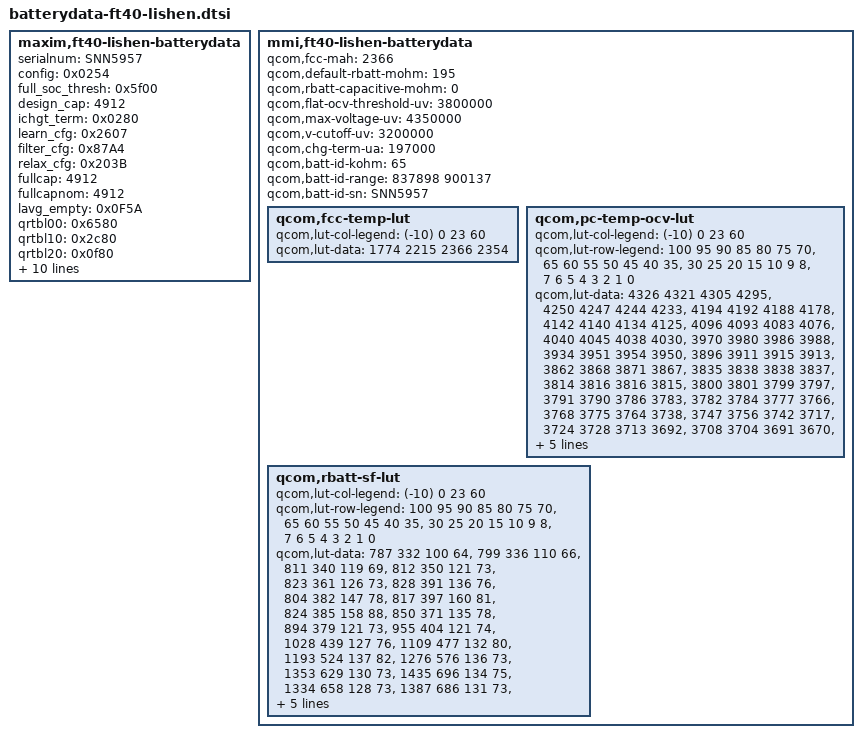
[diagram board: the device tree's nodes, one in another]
/* Copyright (c) 2013-2015, The Linux Foundation. All rights reserved.
 *
 * This program is free software; you can redistribute it and/or modify
 * it under the terms of the GNU General Public License version 2 and
 * only version 2 as published by the Free Software Foundation.
 *
 * This program is distributed in the hope that it will be useful,
 * but WITHOUT ANY WARRANTY; without even the implied warranty of
 * MERCHANTABILITY or FITNESS FOR A PARTICULAR PURPOSE.  See the
 * GNU General Public License for more details.
 */

maxim,ft40-lishen-batterydata {
	/* Required properties */
	serialnum	= "SNN5957";

	/* Table from Maxim for FT40 Lishen 2456 mAhr Battery */
	config		= /bits/ 16 <0x0254>;
	full_soc_thresh	= /bits/ 16 <0x5f00>;	/* app note constant */
	design_cap	= /bits/ 16 <4912>;	/* mAh times 2 */
	ichgt_term	= /bits/ 16 <0x0280>;	/* battery attribute */
	learn_cfg	= /bits/ 16 <0x2607>;	/* app note constant */
	filter_cfg	= /bits/ 16 <0x87A4>;	/* app note constant */
	relax_cfg	= /bits/ 16 <0x203B>;
	fullcap		= /bits/ 16 <4912>;	/* mAh times 2 */
	fullcapnom	= /bits/ 16 <4912>;	/* mAh times 2 */
	lavg_empty	= /bits/ 16 <0x0F5A>;	/* (2456mA/4/0.15625mA) */
	qrtbl00		= /bits/ 16 <0x6580>;	/* battery attribute */
	qrtbl10		= /bits/ 16 <0x2c80>;	/* battery attribute */
	qrtbl20		= /bits/ 16 <0x0f80>;	/* battery attribute */
	qrtbl30		= /bits/ 16 <0x0b00>;	/* battery attribute */
	rcomp0 		= /bits/ 16 <0x003f>;	/* battery attribute */
	tcompc0		= /bits/ 16 <0x1a3d>;	/* battery attribute */
	maxim,cell-char-tbl = /bits/ 16 <	/* battery attribute */
		0x9430 0xb340 0xb790 0xba00 0xbb50 0xbbd0
		0xbda0 0xbea0 0xc000 0xc320 0xc4d0 0xc760
		0xc9d0 0xcce0 0xd160 0xd720 0x0090 0x0600
		0x0d40 0x11a0 0x1910 0x1700 0x1b00 0x12e0
		0x09b0 0x0ce0 0x06e0 0x08e0 0x0790 0x07f0
		0x06e0 0x06e0 0x0200 0x0200 0x0200 0x0200
		0x0200 0x0200 0x0200 0x0200 0x0200 0x0200
		0x0200 0x0200 0x0200 0x0200 0x0200 0x0200
	>;
	/* Optional properties */
	tgain		= /bits/ 16 <0xE71C>;	/* thermistor attribute */
	toff		= /bits/ 16 <0x251A>;	/* thermistor attribute */
	cgain		= /bits/ 16 <0x4000>;	/* current sense attribute */
	misc_cfg	= /bits/ 16 <0x0170>;
	rev		= /bits/ 16 <0x0003>;
};

mmi,ft40-lishen-batterydata {
	qcom,fcc-mah = <2366>;
	qcom,default-rbatt-mohm = <195>;
	qcom,rbatt-capacitive-mohm = <0>;
	qcom,flat-ocv-threshold-uv = <3800000>;
	qcom,max-voltage-uv = <4350000>;
	qcom,v-cutoff-uv = <3200000>;
	qcom,chg-term-ua = <197000>;
	qcom,batt-id-kohm = <65>; /* 64.9 kOhm Round Up */
	qcom,batt-id-range = <837898 900137>;
	qcom,batt-id-sn = "SNN5957";

	qcom,fcc-temp-lut {
		qcom,lut-col-legend = <(-10) 0 23 60>;
		qcom,lut-data = <1774 2215 2366 2354>;
	};

	qcom,pc-temp-ocv-lut {
		qcom,lut-col-legend = <(-10) 0 23 60>;
		qcom,lut-row-legend = <100 95 90 85 80 75 70>,
				<65 60 55 50 45 40 35>,
				<30 25 20 15 10 9 8>,
				<7 6 5 4 3 2 1 0>;
		qcom,lut-data = <4326 4321 4305 4295>,
				<4250 4247 4244 4233>,
				<4194 4192 4188 4178>,
				<4142 4140 4134 4125>,
				<4096 4093 4083 4076>,
				<4040 4045 4038 4030>,
				<3970 3980 3986 3988>,
				<3934 3951 3954 3950>,
				<3896 3911 3915 3913>,
				<3862 3868 3871 3867>,
				<3835 3838 3838 3837>,
				<3814 3816 3816 3815>,
				<3800 3801 3799 3797>,
				<3791 3790 3786 3783>,
				<3782 3784 3777 3766>,
				<3768 3775 3764 3738>,
				<3747 3756 3742 3717>,
				<3724 3728 3713 3692>,
				<3708 3704 3691 3670>,
				<3705 3701 3691 3669>,
				<3702 3700 3690 3667>,
				<3697 3697 3688 3665>,
				<3687 3693 3684 3660>,
				<3665 3678 3667 3639>,
				<3626 3642 3630 3600>,
				<3569 3590 3579 3546>,
				<3492 3520 3511 3479>,
				<3376 3417 3407 3377>,
				<3200 3200 3200 3200>;
	};

	qcom,rbatt-sf-lut {
		qcom,lut-col-legend = <(-10) 0 23 60>;
		qcom,lut-row-legend = <100 95 90 85 80 75 70>,
				<65 60 55 50 45 40 35>,
				<30 25 20 15 10 9 8>,
				<7 6 5 4 3 2 1 0>;
		qcom,lut-data = <787 332 100 64>,
				<799 336 110 66>,
				<811 340 119 69>,
				<812 350 121 73>,
				<823 361 126 73>,
				<828 391 136 76>,
				<804 382 147 78>,
				<817 397 160 81>,
				<824 385 158 88>,
				<850 371 135 78>,
				<894 379 121 73>,
				<955 404 121 74>,
				<1028 439 127 76>,
				<1109 477 132 80>,
				<1193 524 137 82>,
				<1276 576 136 73>,
				<1353 629 130 73>,
				<1435 696 134 75>,
				<1334 658 128 73>,
				<1387 686 131 73>,
				<1468 722 135 74>,
				<1554 767 140 75>,
				<1645 827 146 77>,
				<1731 882 147 80>,
				<1823 942 150 82>,
				<1947 1042 162 79>,
				<2116 1195 172 83>,
				<2427 1446 189 89>,
				<3504 2150 532 161>;
	};
};
